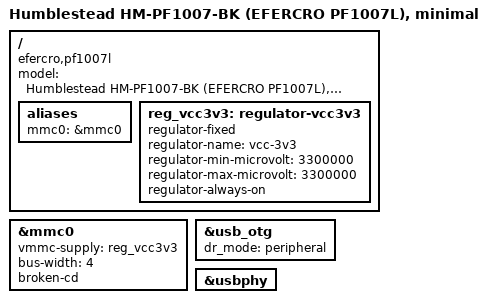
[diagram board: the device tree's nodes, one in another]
// SPDX-License-Identifier: (GPL-2.0+ OR MIT)

/dts-v1/;
#include "sun8i-a33.dtsi"

/ {
	model = "Humblestead HM-PF1007-BK (EFERCRO PF1007L), minimal";
	compatible = "efercro,pf1007l", "allwinner,sun8i-a33";

	aliases {
		mmc0 = &mmc0;
	};

	reg_vcc3v3: regulator-vcc3v3 {
		compatible = "regulator-fixed";
		regulator-name = "vcc-3v3";
		regulator-min-microvolt = <3300000>;
		regulator-max-microvolt = <3300000>;
		regulator-always-on;
	};
};

&mmc0 {
	vmmc-supply = <&reg_vcc3v3>;
	bus-width = <4>;
	broken-cd;
	status = "okay";
};

&usb_otg {
	dr_mode = "peripheral";
	status = "okay";
};

&usbphy {
	status = "okay";
};
